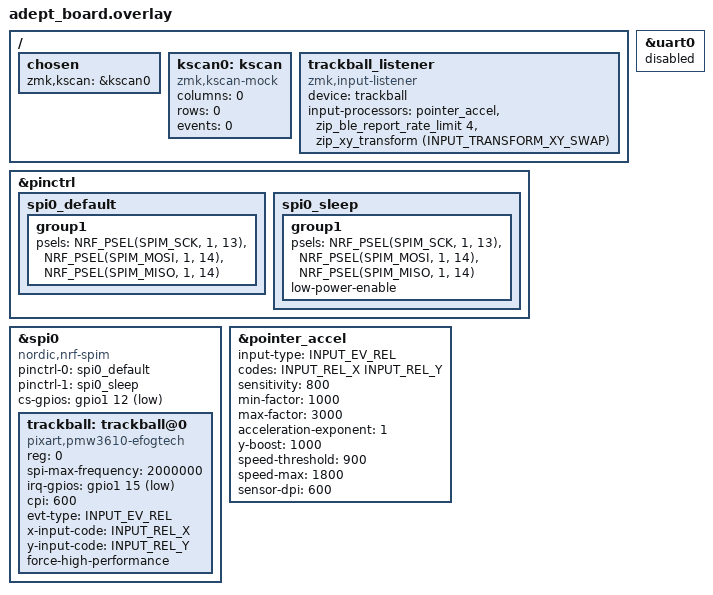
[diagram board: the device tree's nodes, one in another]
#include <dt-bindings/zmk/matrix_transform.h>
#include <input/processors.dtsi>
#include <input/processors/report_rate_limit.dtsi>
#include <dt-bindings/zmk/input_transform.h>
#include <behaviors/input_gestures_accel.dtsi>

#define INPUT_EV_KEY 0x01               /**< Key event */
#define INPUT_EV_REL 0x02               /**< Relative coordinate event */
#define INPUT_EV_ABS 0x03               /**< Absolute coordinate event */
#define INPUT_EV_MSC 0x04               /**< Miscellaneous event */
#define INPUT_EV_VENDOR_START 0xf0      /**< Vendor specific event start */
#define INPUT_EV_VENDOR_STOP 0xff       /**< Vendor specific event stop */

#define INPUT_REL_X 0x00                /**< Relative X coordinate */
#define INPUT_REL_Y 0x01                /**< Relative Y coordinate */
#define INPUT_REL_WHEEL 0x08            /**< Relative wheel coordinate */
#define INPUT_REL_HWHEEL 0x06           /**< Relative horizontal wheel coordinate */
#define INPUT_REL_MISC 0x09             /**< Relative misc coordinate */

&pinctrl {
    spi0_default: spi0_default {
        group1 {
            psels = <NRF_PSEL(SPIM_SCK,  1, 13)>, // SCLK P1.13
                    <NRF_PSEL(SPIM_MOSI, 1, 14)>, // SDIO P1.14
                    <NRF_PSEL(SPIM_MISO, 1, 14)>; // SDIO P1.14
        };
    };

    spi0_sleep: spi0_sleep {
        group1 {
            psels = <NRF_PSEL(SPIM_SCK,  1, 13)>, // SCLK P1.13
                    <NRF_PSEL(SPIM_MOSI, 1, 14)>, // SDIO P1.14
                    <NRF_PSEL(SPIM_MISO, 1, 14)>; // SDIO P1.14
            low-power-enable;
        };
    };
};

#include <zephyr/dt-bindings/input/input-event-codes.h>

&spi0 {
    status = "okay";
    compatible = "nordic,nrf-spim";
    pinctrl-0 = <&spi0_default>;
    pinctrl-1 = <&spi0_sleep>;
    pinctrl-names = "default", "sleep";
    cs-gpios = <&gpio1 12 GPIO_ACTIVE_LOW>; // NCS P1.12

    trackball: trackball@0 {
        status = "okay";
        compatible = "pixart,pmw3610-efogtech";
        reg = <0>;
        spi-max-frequency = <2000000>;
        irq-gpios = <&gpio1 15 (GPIO_ACTIVE_LOW | GPIO_PULL_UP)>; // MOT P1.15
        cpi = <600>;
        evt-type = <INPUT_EV_REL>;
        x-input-code = <INPUT_REL_X>;
        y-input-code = <INPUT_REL_Y>;

        // force-awake will cause warping and cursor jumping. Don't recommend now.
        force-high-performance;
    };
};

&pointer_accel { // this needs to be put BEFORE input-listener
    input-type = <INPUT_EV_REL>;
    codes = <INPUT_REL_X INPUT_REL_Y>;
    sensitivity = <800>;         // 0.8x base sensitivity
	min-factor = <800>;			  // 0.8x minimum for percision
    max-factor = <3000>;          // 3.0x maximum acceleration
    acceleration-exponent = <1>;  // Advanced exponential curve (1-5)
    y-boost = <1000>;             // 1.0x Y-axis boost for widescreen
    speed-threshold = <900>;      // Start acceleration at 900 counts/sec, just 1.5 inch/sec
    speed-max = <1800>;           // Max acceleration at 1800 counts/sec, just 3 inch/sec
    min-factor = <1000>;          // 1.0x minimum (no deceleration)
	sensor-dpi = <600>;
};

/* More about input processors: https://zmk.dev/docs/keymaps/input-processors#input-processors-overview */

/ {
    chosen {
        zmk,kscan = &kscan0;
    };

    kscan0: kscan {
        compatible = "zmk,kscan-mock";
        columns = <0>;
        rows = <0>;
        events = <0>;
    };

    trackball_listener { // listener for input device
        compatible = "zmk,input-listener";
        device = <&trackball>;
        input-processors =
            <&pointer_accel>,
            <&zip_ble_report_rate_limit 4>, // from badjeff's https://github.com/badjeff/zmk-input-processor-report-rate-limit/blob/main/dts/input/processors/report_rate_limit.dtsi
            <&zip_xy_transform (INPUT_TRANSFORM_XY_SWAP)>;

    };
};

/* Disable UART to avoid pin conflicts */
&uart0 {
    status = "disabled";
};
